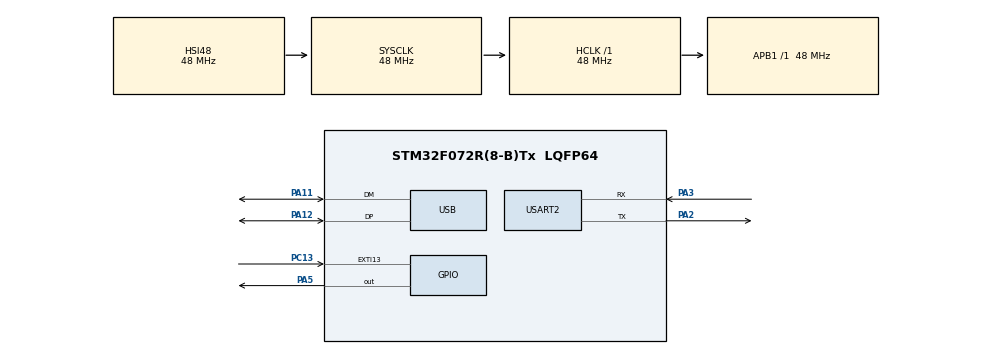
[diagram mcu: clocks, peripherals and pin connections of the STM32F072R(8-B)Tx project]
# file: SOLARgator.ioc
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FREERTOS.Tasks01=blink01,24,128,StartBlink01,Default,NULL,Dynamic,NULL,NULL;blink02,16,128,StartBlink02,Default,NULL,Dynamic,NULL,NULL
Mcu.Family=STM32F0
Mcu.Name=STM32F072R(8-B)Tx
Mcu.Package=LQFP64
NVIC.TIM6_DAC_IRQn=true\:0\:0\:false\:false\:true\:false\:false\:true
NVIC.TimeBase=TIM6_DAC_IRQn
NVIC.TimeBaseIP=TIM6
NVIC.USB_IRQn=true\:3\:0\:false\:false\:true\:true\:false\:true
PA11.Mode=Device
PA11.Signal=USB_DM
PA12.Mode=Device
PA12.Signal=USB_DP
PA13.Mode=Serial_Wire
PA13.Signal=SYS_SWDIO
PA14.Mode=Serial_Wire
PA14.Signal=SYS_SWCLK
PA2.GPIO_Mode=GPIO_MODE_AF_PP
PA2.GPIO_ModeDefaultPP=GPIO_MODE_AF_PP
PA2.GPIO_PuPd=GPIO_NOPULL
PA2.GPIO_Speed=GPIO_SPEED_FREQ_HIGH
PA2.Mode=Asynchronous
PA2.Signal=USART2_TX
PA3.GPIO_Mode=GPIO_MODE_AF_PP
PA3.GPIO_ModeDefaultPP=GPIO_MODE_AF_PP
PA3.GPIO_PuPd=GPIO_NOPULL
PA3.GPIO_Speed=GPIO_SPEED_FREQ_HIGH
PA3.Mode=Asynchronous
PA3.Signal=USART2_RX
PA5.GPIO_Mode=GPIO_MODE_OUTPUT_PP
PA5.GPIO_ModeDefaultOutputPP=GPIO_MODE_OUTPUT_PP
PA5.GPIO_PuPd=GPIO_NOPULL
PA5.GPIO_Speed=GPIO_SPEED_FREQ_LOW
PA5.PinState=GPIO_PIN_RESET
PA5.Signal=GPIO_Output
PC13.GPIO_ModeDefaultEXTI=GPIO_MODE_IT_RISING
PC13.GPIO_PuPd=GPIO_NOPULL
PC13.Signal=GPXTI13
PC14-OSC32_IN.Mode=LSE-External-Oscillator
PC14-OSC32_IN.Signal=RCC_OSC32_IN
PC15-OSC32_OUT.Mode=LSE-External-Oscillator
PC15-OSC32_OUT.Signal=RCC_OSC32_OUT
PF0-OSC_IN.Mode=HSE-External-Clock-Source
PF0-OSC_IN.Signal=RCC_OSC_IN
PF1-OSC_OUT.Signal=RCC_OSC_OUT
ProjectManager.HeapSize=0x200
ProjectManager.StackSize=0x400
ProjectManager.TargetToolchain=STM32CubeIDE
RCC.AHBFreq_Value=48000000
RCC.APB1Freq_Value=48000000
RCC.APB1TimFreq_Value=48000000
RCC.FLatency-AdvancedSettings=FLASH_LATENCY_1
RCC.HCLKFreq_Value=48000000
RCC.PLLDivider=RCC_PREDIV_DIV2
RCC.PLLMUL=RCC_PLL_MUL12
RCC.PREFETCH_ENABLE-AdvancedSettings=1
RCC.SYSCLKFreq_VALUE=48000000
RCC.SYSCLKSource=RCC_SYSCLKSOURCE_HSI48
USART2.VirtualMode=VM_ASYNC
USART2.VirtualMode-Asynchronous=VM_ASYNC
USB_DEVICE.CLASS_NAME_FS=CDC
USB_DEVICE.VirtualMode=Cdc
USB_DEVICE.VirtualModeFS=Cdc_FS
VP_FREERTOS_VS_CMSIS_V2.Mode=CMSIS_V2
VP_SYS_VS_tim6.Mode=TIM6
VP_USB_DEVICE_VS_USB_DEVICE_CDC_FS.Mode=CDC_FS
board=NUCLEO-F072RB

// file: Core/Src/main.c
/* USER CODE BEGIN Header */
/**
  ******************************************************************************
  * @file           : main.c
  * @brief          : Main program body
  ******************************************************************************
  * @attention
  *
  * <h2><center>&copy; Copyright (c) 2020 STMicroelectronics.
  * All rights reserved.</center></h2>
  *
  * This software component is licensed by ST under BSD 3-Clause license,
  * the "License"; You may not use this file except in compliance with the
  * License. You may obtain a copy of the License at:
  *                        opensource.org/licenses/BSD-3-Clause
  *
  ******************************************************************************
  */
/* USER CODE END Header */

#include "main.h"
#include "cmsis_os.h"
#include "usb_device.h"

UART_HandleTypeDef huart2;

/* Definitions for blink01 */
osThreadId_t blink01Handle;
const osThreadAttr_t blink01_attributes = {
  .name = "blink01",
  .priority = (osPriority_t) osPriorityNormal,
  .stack_size = 128
};
/* Definitions for blink02 */
osThreadId_t blink02Handle;
const osThreadAttr_t blink02_attributes = {
  .name = "blink02",
  .priority = (osPriority_t) osPriorityBelowNormal,
  .stack_size = 128
};

void SystemClock_Config(void);
static void MX_GPIO_Init(void);
static void MX_USART2_UART_Init(void);
void StartBlink01(void *argument);
void StartBlink02(void *argument);

int main(void)
{

  /* MCU Configuration--------------------------------------------------------*/

  /* Reset of all peripherals, Initializes the Flash interface and the Systick. */
  HAL_Init();

  /* Configure the system clock */
  SystemClock_Config();

  /* Initialize all configured peripherals */
  MX_GPIO_Init();
  MX_USART2_UART_Init();
  /* Init scheduler */
  osKernelInitialize();

  /* Create the thread(s) */
  /* creation of blink01 */
  blink01Handle = osThreadNew(StartBlink01, NULL, &blink01_attributes);

  /* creation of blink02 */
  blink02Handle = osThreadNew(StartBlink02, NULL, &blink02_attributes);

  /* Start scheduler */
  osKernelStart();

  /* We should never get here as control is now taken by the scheduler */

  /* Infinite loop */
  while (1)
  {

  }
}

void SystemClock_Config(void)
{
  RCC_OscInitTypeDef RCC_OscInitStruct = {0};
  RCC_ClkInitTypeDef RCC_ClkInitStruct = {0};
  RCC_PeriphCLKInitTypeDef PeriphClkInit = {0};

  /** Initializes the CPU, AHB and APB busses clocks
  */
  RCC_OscInitStruct.OscillatorType = RCC_OSCILLATORTYPE_HSI48;
  RCC_OscInitStruct.HSI48State = RCC_HSI48_ON;
  RCC_OscInitStruct.PLL.PLLState = RCC_PLL_NONE;
  if (HAL_RCC_OscConfig(&RCC_OscInitStruct) != HAL_OK)
  {
    Error_Handler();
  }
  /** Initializes the CPU, AHB and APB busses clocks
  */
  RCC_ClkInitStruct.ClockType = RCC_CLOCKTYPE_HCLK|RCC_CLOCKTYPE_SYSCLK
                              |RCC_CLOCKTYPE_PCLK1;
  RCC_ClkInitStruct.SYSCLKSource = RCC_SYSCLKSOURCE_HSI48;
  RCC_ClkInitStruct.AHBCLKDivider = RCC_SYSCLK_DIV1;
  RCC_ClkInitStruct.APB1CLKDivider = RCC_HCLK_DIV1;

  if (HAL_RCC_ClockConfig(&RCC_ClkInitStruct, FLASH_LATENCY_1) != HAL_OK)
  {
    Error_Handler();
  }
  PeriphClkInit.PeriphClockSelection = RCC_PERIPHCLK_USB|RCC_PERIPHCLK_USART2;
  PeriphClkInit.Usart2ClockSelection = RCC_USART2CLKSOURCE_PCLK1;
  PeriphClkInit.UsbClockSelection = RCC_USBCLKSOURCE_HSI48;

  if (HAL_RCCEx_PeriphCLKConfig(&PeriphClkInit) != HAL_OK)
  {
    Error_Handler();
  }
}

static void MX_USART2_UART_Init(void)
{

  huart2.Instance = USART2;
  huart2.Init.BaudRate = 38400;
  huart2.Init.WordLength = UART_WORDLENGTH_8B;
  huart2.Init.StopBits = UART_STOPBITS_1;
  huart2.Init.Parity = UART_PARITY_NONE;
  huart2.Init.Mode = UART_MODE_TX_RX;
  huart2.Init.HwFlowCtl = UART_HWCONTROL_NONE;
  huart2.Init.OverSampling = UART_OVERSAMPLING_16;
  huart2.Init.OneBitSampling = UART_ONE_BIT_SAMPLE_DISABLE;
  huart2.AdvancedInit.AdvFeatureInit = UART_ADVFEATURE_NO_INIT;
  if (HAL_UART_Init(&huart2) != HAL_OK)
  {
    Error_Handler();
  }

}

static void MX_GPIO_Init(void)
{
  GPIO_InitTypeDef GPIO_InitStruct = {0};

  /* GPIO Ports Clock Enable */
  __HAL_RCC_GPIOC_CLK_ENABLE();
  __HAL_RCC_GPIOF_CLK_ENABLE();
  __HAL_RCC_GPIOA_CLK_ENABLE();

  /*Configure GPIO pin Output Level */
  HAL_GPIO_WritePin(GPIOA, GPIO_PIN_5, GPIO_PIN_RESET);

  /*Configure GPIO pin : PC13 */
  GPIO_InitStruct.Pin = GPIO_PIN_13;
  GPIO_InitStruct.Mode = GPIO_MODE_IT_RISING;
  GPIO_InitStruct.Pull = GPIO_NOPULL;
  HAL_GPIO_Init(GPIOC, &GPIO_InitStruct);

  /*Configure GPIO pin : PA5 */
  GPIO_InitStruct.Pin = GPIO_PIN_5;
  GPIO_InitStruct.Mode = GPIO_MODE_OUTPUT_PP;
  GPIO_InitStruct.Pull = GPIO_NOPULL;
  GPIO_InitStruct.Speed = GPIO_SPEED_FREQ_LOW;
  HAL_GPIO_Init(GPIOA, &GPIO_InitStruct);

}

void StartBlink01(void *argument)
{
  /* init code for USB_DEVICE */
  MX_USB_DEVICE_Init();
  /* USER CODE BEGIN 5 */
  /* Infinite loop */
//  for(;;)
//  {
//    osDelay(60);
//    HAL_GPIO_TogglePin(GPIOA, GPIO_PIN_5);
//
//  }
  /* USER CODE END 5 */
}

void StartBlink02(void *argument)
{
  /* USER CODE BEGIN StartBlink02 */
  /* Infinite loop */
//  for(;;)
//  {
//    osDelay(50);
//    HAL_GPIO_TogglePin(GPIOA, GPIO_PIN_5);
//  }
  /* USER CODE END StartBlink02 */
}

void HAL_TIM_PeriodElapsedCallback(TIM_HandleTypeDef *htim)
{
  if (htim->Instance == TIM6) {
    HAL_IncTick();
  }
}

void Error_Handler(void)
{
}

/************************ (C) COPYRIGHT STMicroelectronics *****END OF FILE****/
